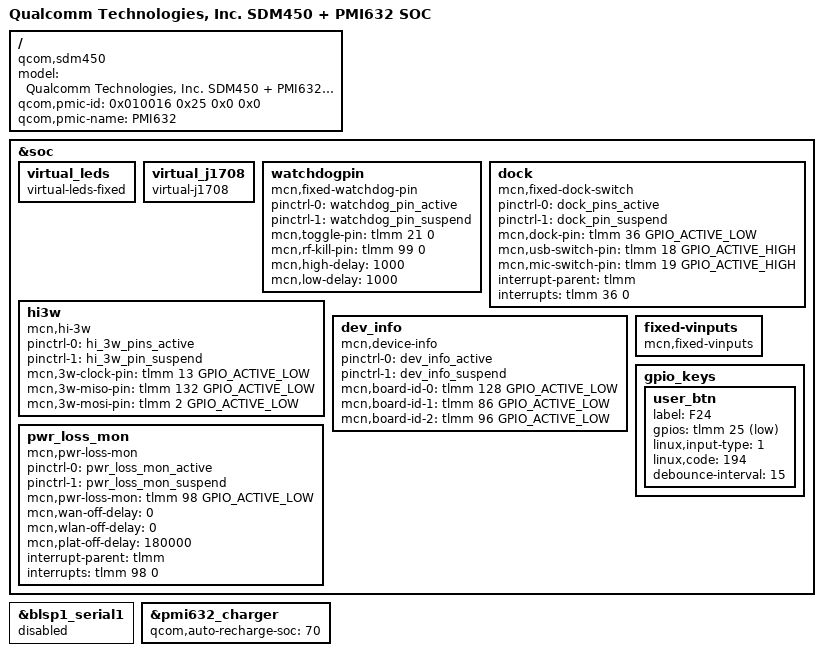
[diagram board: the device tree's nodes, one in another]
/*
 * Copyright (c) 2018, The Linux Foundation. All rights reserved.
 *
 * This program is free software; you can redistribute it and/or modify
 * it under the terms of the GNU General Public License version 2 and
 * only version 2 as published by the Free Software Foundation.
 *
 * This program is distributed in the hope that it will be useful,
 * but WITHOUT ANY WARRANTY; without even the implied warranty of
 * MERCHANTABILITY or FITNESS FOR A PARTICULAR PURPOSE.  See the
 * GNU General Public License for more details.
 */

/dts-v1/;

#include "sdm450.dtsi"
#include "sdm450-pmi632.dtsi"
#include "msm8953-pmi632-panel-camera.dtsi"

/ {
	model = "Qualcomm Technologies, Inc. SDM450 + PMI632 SOC";
	compatible = "qcom,sdm450";
	qcom,pmic-id = <0x010016 0x25 0x0 0x0>;
	qcom,pmic-name = "PMI632";
};

&soc {
	virtual_leds {
		compatible = "virtual-leds-fixed";
		status = "okay";
	};

	virtual_j1708 {
		compatible = "virtual-j1708";
		status = "okay";
	};

	watchdogpin {
		compatible = "mcn,fixed-watchdog-pin";
		pinctrl-names = "watchdog_pin_active", "watchdog_pin_suspend";
		pinctrl-0 = <&watchdog_pin_active>;		
		pinctrl-1 = <&watchdog_pin_suspend>;
		mcn,toggle-pin = <&tlmm 21 0>;
		mcn,rf-kill-pin = <&tlmm 99 0>;
		mcn,high-delay=<1000>;
		mcn,low-delay=<1000>;
		status = "okay";
	};

	dock {
		compatible = "mcn,fixed-dock-switch";
		pinctrl-names = "dock_pins_active", "dock_pin_suspend";
		pinctrl-0 = <&dock_pins_active>;
		pinctrl-1 = <&dock_pin_suspend>;
		mcn,dock-pin = <&tlmm 36 GPIO_ACTIVE_LOW>;
		/* usb switch hw controlled by vbus_cradle signal */
		mcn,usb-switch-pin = <&tlmm 18 GPIO_ACTIVE_HIGH>;
		/*mcn,otg-en-pin = <&tlmm 97 GPIO_ACTIVE_HIGH>;*/
		mcn,mic-switch-pin = <&tlmm 19 GPIO_ACTIVE_HIGH>;
		interrupt-names = "cradle-detect";
		interrupt-parent = <&tlmm>;
		interrupts = <&tlmm 36 0>;
		status = "okay";
	};

	hi3w {
		compatible = "mcn,hi-3w";
		pinctrl-names = "hi_3w_pins_active", "hi_3w_pin_suspend";
		pinctrl-0 = <&hi_3w_pins_active>;
		pinctrl-1 = <&hi_3w_pin_suspend>;
		mcn,3w-clock-pin = <&tlmm 13 GPIO_ACTIVE_LOW>;
		mcn,3w-miso-pin = <&tlmm 132 GPIO_ACTIVE_LOW>;
		mcn,3w-mosi-pin = <&tlmm 2 GPIO_ACTIVE_LOW>;
		status = "okay";
	};

	dev_info {
		compatible = "mcn,device-info";
		pinctrl-names = "dev_info_active", "dev_info_suspend";
		pinctrl-0 = <&dev_info_active>;
		pinctrl-1 = <&dev_info_suspend>;
		mcn,board-id-0 = <&tlmm 128 GPIO_ACTIVE_LOW>;
		mcn,board-id-1 = <&tlmm 86 GPIO_ACTIVE_LOW>;
		mcn,board-id-2 = <&tlmm 96 GPIO_ACTIVE_LOW>; 
		status = "okay";
	};

	pwr_loss_mon {
		compatible = "mcn,pwr-loss-mon";
		pinctrl-names = "pwr_loss_mon_active", "pwr_loss_mon_suspend";
		pinctrl-0 = <&pwr_loss_mon_active>;
		pinctrl-1 = <&pwr_loss_mon_suspend>;
		mcn,pwr-loss-mon = <&tlmm 98 GPIO_ACTIVE_LOW>; 
		mcn,wan-off-delay = <0>;
		mcn,wlan-off-delay = <0>;
		mcn,plat-off-delay = <180000>;
		interrupt-names = "pwr-loss";
		interrupt-parent = <&tlmm>;
		interrupts = <&tlmm 98 0>;
		status = "okay";
	};

	fixed-vinputs {
		compatible = "mcn,fixed-vinputs";
		status = "okay";
	};

	gpio_keys {
		user_btn {
			label = "F24";
			gpios = <&tlmm 25 0x1>;
			linux,input-type = <1>;
			linux,code = <194>;
			debounce-interval = <15>;
		};
	};
};

&blsp1_serial1 {
	status = "disabled";
};

/*
&pm8953_rtc {
	qcom,qpnp-rtc-write = <1>;
	qcom,qpnp-rtc-alarm-pwrup = <1>;
}
*/

&pmi632_charger {
	qcom,auto-recharge-soc = <70>;
};
